# ET6801 register map
Vendor: ETMCU Inc.; File version: v0.0.1
CPU: CM7 r2p1, little endian, MPU, FPU, I-cache, D-cache, ITCM, DTCM, 4 interrupt priority bits
Registers are 32-bit, read-write, reset 0x0 unless marked. A register's access mark holds for its fields unless they carry their own. Offsets are from the block's base; [hi:lo] are bit positions; lines under a group give offsets from that group; {n}, {i} and the like mark numbered series.

## IPCM — Provide an overview of the purpose and functionality of the peripheral: ipcm_cfg
Base 0x40208000
{0x0+0x40*i} IPCMX_PARA[{i}] (i=0..15) group
  0x00 IPCMXSOURCE
    [31:0] SOURCE — Set to define which core is the source and which interrupt line is asserted for the acknowledge interrupt
  0x04 IPCMXDSET
    [31:0] DESTINATIONSET wo — Used to set bits in the IPCMxDSTATUS Registers
  0x08 IPCMXDCLEAR
    [31:0] DESTINATIONCLEAR wo — Used to clear bits in the IPCMxDSTATUS Registers
  0x0C IPCMXDSTATUS ro
    [31:0] DESTINATIONSTATUS — Gives the status of the Mailbox Destination Register. Defines which interrupt output to assert for the message.
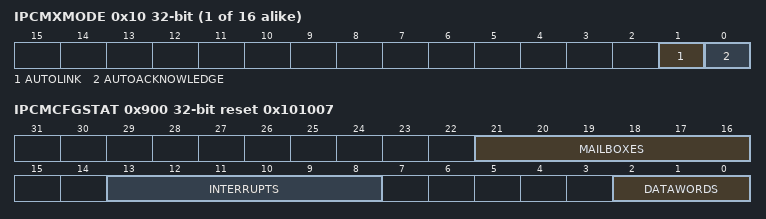
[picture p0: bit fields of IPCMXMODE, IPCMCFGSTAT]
  0x10 IPCMXMODE
    [1] AUTOLINK — Set to enable Auto Link.
    [0] AUTOACKNOWLEDGE — Set to enable Auto Acknowledge.
  0x14 IPCMXMSET
    [31:0] MASKSET wo — Used to set bits in the Mailbox Mask Register
  0x18 IPCMXMCLEAR
    [31:0] MASKCLEAR wo — Used to clear bits in the Mailbox Mask Register
  0x1C IPCMXMSTATUS ro
    [31:0] MASKSTATUS — Gives the status of the Mailbox Mask Registers. For each bit position: 1 = Mailbox interrupt enabled 0 = Mailbox interrupt disabled, polling used instead.
  0x20 IPCMXSEND
    [1:0] SEND — Send message: 00 = inactive 01 = send message to destination core(s) 10 = send message to source core 11 = invalid, unpredictable behavior
  {0x24+4j} IPCMXDR{j} (j=0..6)
    [31:0] DATA{j} — Message data{j}
{0x800+8i} INTERRUPTX_STATUS[{i}] (i=0..15) group
  0x00 IPCMMISX ro
    [31:0] MASKINTSTAT — Masked interrupt status
  0x04 IPCMRISX ro
    [31:0] RAWINTSTAT — Raw interrupt status
0x900 IPCMCFGSTAT ro reset 0x101007
  [21:16] MAILBOXES — Returns the value of the MBOXNUM input pins
  [13:8] INTERRUPTS — Returns the value of the INTNUM input pins
  [2:0] DATAWORDS — Returns the value of the DATANUM input pins

## SPINLOCK — Provide an overview of the purpose and functionality of the peripheral: spinlock_cfg
Base 0x40209000
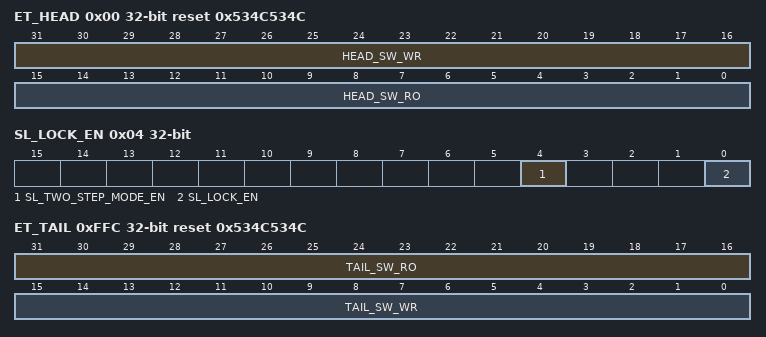
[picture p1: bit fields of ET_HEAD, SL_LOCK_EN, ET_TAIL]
0x00 ET_HEAD reset 0x534C534C
  [31:16] HEAD_SW_WR — 软件测试读写寄存器，硬件无访问
  [15:0] HEAD_SW_RO ro — 软件只读上报寄存器，硬件无访问,SpinLock的SL ASICII 码表示
0x04 SL_LOCK_EN
  [4] SL_TWO_STEP_MODE_EN — 要求wdata[20]同时为1时，才能更新该参数 1表示SpinLock模块进入2步法锁定工作模式 0表示SpinLock模块进入单步法锁定工作模式
  [0] SL_LOCK_EN — 要求wdata[16]同时为1时，才能更新该参数 1表示使能SpinLock模块进入工作状态 0表示SpinLock模块退出工作状态 SpinLock模块不管是进入还是退出工作状态，不会对现有SPIN_LOCK上报的状态造成改变
0x08 SL_BATCH_LOCK_CLR
  [31:0] SL_LOCK_CLR_KEY — 当写入sl_lock_clr_key = 0x67891230时，会将运行该操作对应的CPU之前已经占用的SPIN_LOCK资源全部解锁； 该寄存器回读是0值；
0x0C SL_GLOBAL_LOCK_CLR
  [31:0] SL_LOCK_GLB_CLR_KEY — 当写入sl_lock_glb_clr_key = 0xCDEF1230时，不会判断运行CPU的MASTER ID；直接会解锁所有SPINLOCK资源，该功能只能用于SPIN LOCK初始化；该寄存器回读是0值；
0x10 SL_LOCK_FLAG_RPT1 ro
  [31:0] SL_LOCK_FLAG1 — [31:0]对应SPIN_LOCK RESOURCE 31~0的LOCK状态上报
0x14 SL_LOCK_FLAG_RPT2 ro
  [31:0] SL_LOCK_FLAG2 — [31:0]对应SPIN_LOCK RESOURCE 63~32的LOCK状态上报
{0x800+4i} SL_LOCK_INFO_ARRAY[{i}] (i=0..63) group
  0x00 SL_LOCK_INFO
    [31:0] SL_LOCK_INFO — bit31: 写0表示解锁对应RESOURCE的LOCK标志 bit[15:8] : 对应RESOURCE的LOCK的MASTER ID bit7: 对应RESOURCE的PROCESS ID 初始化标志（1表示完成PROCESS ID写入，0表示未完成PROCESS ID写入），状态=1只在SPIN_LOCK=2步锁定使用 bit[3:0] : 对应RESOURCE的LOCK的PROCESS ID（软件先取得对应RESOURCE的锁定权后，才能通过[3:0]写入PROCESS ID） 当软件读取SL_LOCK_INFO时，如果该RESOURCE是空闲状态，则会自动进入LOCK状态，并记录该软件运行CPU的MASTER ID信息，RESOURCE进入LOCK状态后，只有之前加锁的运行CPU才能解锁LOCK状态。
0xFFC ET_TAIL reset 0x534C534C
  [31:16] TAIL_SW_RO ro — 软件只读硬件上报寄存器
  [15:0] TAIL_SW_WR — 软件测试读写寄存器，硬件无访问

## GPIOA — Provide an overview of the purpose and functionality of the peripheral: gpio_cfg
Base 0x40210000
Same registers: GPIOB 0x40211000, GPIOC 0x40212000, GPIOD 0x40213000, GPIOE 0x40214000, GPIOF 0x40215000, GPIOG 0x40216000, GPIOH 0x40217000, GPIOI 0x40218000
0x00 DATA
  [15:0] DATA — Data value [15:0]: Read Sampled at pin. Write To data output register. Read back value goes through double flip-flop synchronization logic with a delay of two cycles.
0x04 DATAOUT
  [15:0] DATAOUT — Data output Register value [15:0]: Read Current value of data output register. Write To data output register.
0x10 OUTENSET
  [15:0] OUTENSET — Output enable set [15:0]: Write 1 Set the output enable bit. 0 No effect. Read back 0 Indicates the signal direction as input. 1 Indicates the signal direction as output.
0x14 OUTENCLR
  [15:0] OUTENCLR — Output enable clear [15:0]: Write 1 Clears the output enable bit. 0 No effect. Read back 0 Indicates the signal direction as input. 1 Indicates the signal direction as output
0x18 RESERVE1
  [15:0] RESERVE1
0x1C RESERVE2
  [15:0] RESERVE2
0x20 INTENSET
  [15:0] INTENSET — nterrupt enable set [15:0]: Write 1 Sets the enable bit. 0 No effect. Read back 0 Interrupt disabled. 1 Interrupt enabled.
0x24 INTENCLR
  [15:0] INTENCLR — Interrupt enable clear [15:0]: Write 1 Clear the enable bit. 0 No effect. Read back 0 Interrupt disabled. 1 Interrupt enabled.
0x28 INTTYPESET
  [15:0] INTTYPESET — Interrupt type set [15:0]: Write 1 Sets the interrupt type bit. 0 No effect. Read back 0 For LOW or HIGH level. 1 For falling edge or rising edge.
0x2C INTTYPECLR
  [15:0] INTTYPECLR — Interrupt type clear [15:0]: Write 1 Clears the interrupt type bit. 0 No effect. Read back 0 For LOW or HIGH level. 1 For falling edge or rising edge.
0x30 INTPOLSET
  [15:0] INTPOLSET — Polarity-level, edge IRQ configuration [15:0]: Write 1 Sets the interrupt polarity bit. 0 No effect. Read back 0 For LOW level or falling edge. 1 For HIGH level or rising edge.
0x34 INTPOLCLR
  [15:0] INTPOLCLR — Polarity-level, edge IRQ configuration [15:0]: Write 1 Clears the interrupt polarity bit. 0 No effect. Read back 0 For LOW level or falling edge. 1 For HIGH level or rising edge.
0x38 INTSTATUS_INT_CLEAR
  [15:0] INTSTATUS_INT_CLEAR — Write one to clear interrupt request: Write [15:0] IRQ status clear Register. Write: 1 To clear the interrupt request. 0 No effect. Read back [15:0] IRQ status Register.
{0x400+4i} MASKLOWBYTE[{i}] (i=0..255) group
  0x00 MASKLOWBYTE
    [15:0] MASKLOWBYTE — Lower 8 bits masked access. Bits[9:2] of the address value are used as enable bit mask for the access: [15:8] Not used. RAZ/WI. [7:0] Data for lower byte access, with bits[9:2] of address value that is used as enable mask for each bit.
{0x800+4i} MASKHIGHBYTE[{i}] (i=0..255) group
  0x00 MASKHIGHBYTE
    [15:0] MASKHIGHBYTE — Higher 8 bits masked access. Bits[9:2] of the address value are used as enable bit mask for the access: [15:8] Data for higher byte access, with bits[9:2] of address value that is used as enable mask for each bit. [7:0] Not used. RAZ/WI.
